# f2838x_flash_pump_semaphore_regs register map
Vendor: Texas Instruments
Peripheral module from a debugger description file (folder C2000).
Address unit: 16 bits
Registers are 32-bit, read-write, no defined reset value unless marked. A register's access mark holds for its fields unless they carry their own. Offsets are as the file gives them; lines under a group give offsets from that group; [hi:lo] are bit positions; {n}, {i} and the like mark numbered series; 'fields as' and 'values as' point back to an identical list; <NAME> marks a mode.

## FLASH_PUMP_SEMAPHORE_REGS — FLASH PUMP SEMAPHORE Registers
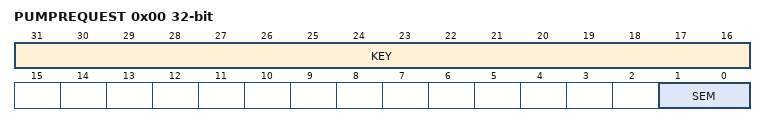
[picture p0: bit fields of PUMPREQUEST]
0x00 PUMPREQUEST — Flash programming semaphore PUMP request register
  [31:16] KEY — Key Qualifier for writes to this register
  [1:0] SEM — Flash Pump Request Semaphore between CPU1, CPU2 and CM
